AUTOSAR XML (schema 4-0-3)
standard types defined: Boolean, UInt32
package /AUTOSAR_Platform/DataConstrs
  range DC_Boolean: raw 0..1
package /PATAC/MSM/ComponentTypes
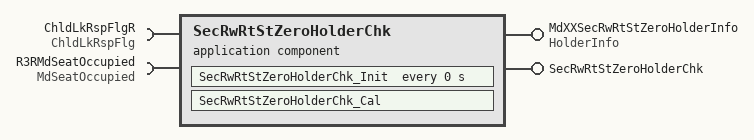
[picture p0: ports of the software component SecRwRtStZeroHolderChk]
  application sw component type SecRwRtStZeroHolderChk
    provide port MdXXSecRwRtStZeroHolderInfo: nonqueued-sender-com-spec{data-element=HolderInfo/Val, init-value=0}, provided-interface=HolderInfo
    provide port SecRwRtStZeroHolderChk: server-com-spec{operation=Cal, queue-length=1}, provided-interface=SecRwRtStZeroHolderChk
    require port ChldLkRspFlgR: nonqueued-receiver-com-spec{data-element=ChldLkRspFlg/Val, filter=data-filter-type=ALWAYS, init-value=0}, required-interface=ChldLkRspFlg
    require port R3RMdSeatOccupied: nonqueued-receiver-com-spec{data-element=MdSeatOccupied/Val, filter=data-filter-type=ALWAYS, init-value=0}, required-interface=MdSeatOccupied
    behavior SecRwRtStZeroHolderChk_InternalBehavior
      operation invoked event OIT_SecRwRtStZeroHolderChk_Cal_SecRwRtStZeroHolderChk_Cal: start-on-event=SecRwRtStZeroHolderChk_Cal, operation=SecRwRtStZeroHolderChk.Cal
      timing event SecRwRtStZeroHolderChk_InitEvent: start-on-event=SecRwRtStZeroHolderChk_Init, period=0
      runnable SecRwRtStZeroHolderChk_Cal
        data-receive-point-by-arguments:
          access REC_ChldLkRspFlgR_Val: accessed-variable=ChldLkRspFlgR.Val
          access REC_R3RMdSeatOccupied_Val: accessed-variable=R3RMdSeatOccupied.Val
        data-send-points:
          access SEND_MdXXSecRwRtStZeroHolderInfo_Val: accessed-variable=MdXXSecRwRtStZeroHolderInfo.Val
      runnable SecRwRtStZeroHolderChk_Init
  swc implementation SecRwRtStZeroHolderChk_Implementation: behavior=SecRwRtStZeroHolderChk_InternalBehavior
    code-descriptors:
      code Default: artifact-descriptors=autosar-engineering-object={short-label=Default, category=SWSRC}
package /PATAC/MSM/ModeAdjust/PortInterface
  client server interface SecRwRtStZeroHolderChk
    operation Cal
  sender receiver interface ChldLkRspFlg: invalidation-policy{data-element=ChldLkRspFlg/Val, handle-invalid=DONT-INVALIDATE}
    data Val: type=Boolean
  sender receiver interface HolderInfo: invalidation-policy{data-element=HolderInfo/Val, handle-invalid=DONT-INVALIDATE}
    data Val: type=UInt32
  sender receiver interface MdSeatOccupied: invalidation-policy{data-element=MdSeatOccupied/Val, handle-invalid=DONT-INVALIDATE}
    data Val: type=Boolean
